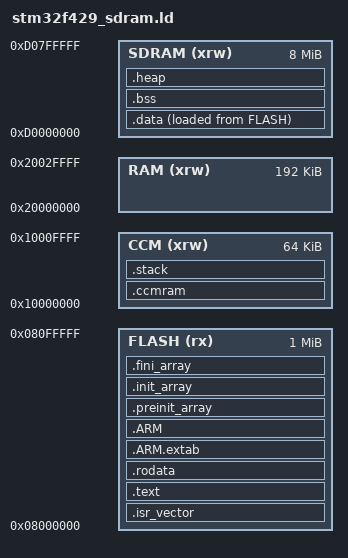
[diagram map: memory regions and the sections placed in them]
/* GNU ARM linker script for fire-f429 applications using onboard SDRAM. */

ENTRY(Reset_Handler)

MEMORY
{
  FLASH  (rx)  : ORIGIN = 0x08000000, LENGTH = 1024K
  RAM    (xrw) : ORIGIN = 0x20000000, LENGTH = 192K
  CCM    (xrw) : ORIGIN = 0x10000000, LENGTH = 64K
  SDRAM  (xrw) : ORIGIN = 0xD0000000, LENGTH = 8M
}

_estack = ORIGIN(CCM) + LENGTH(CCM);
_eram = ORIGIN(SDRAM) + LENGTH(SDRAM);
_Min_Heap_Size = 0x400;
_Min_Stack_Size = 0x1000;

SECTIONS
{
  .isr_vector :
  {
    . = ALIGN(4);
    KEEP(*(.isr_vector))
    . = ALIGN(4);
  } >FLASH

  .text :
  {
    . = ALIGN(4);
    *(.text)
    *(.text*)
    *(.glue_7)
    *(.glue_7t)
    *(.eh_frame)
    KEEP(*(.init))
    KEEP(*(.fini))
    . = ALIGN(4);
    _etext = .;
  } >FLASH

  .rodata :
  {
    . = ALIGN(4);
    *(.rodata)
    *(.rodata*)
    . = ALIGN(4);
  } >FLASH

  .ARM.extab : { *(.ARM.extab* .gnu.linkonce.armextab.*) } >FLASH
  .ARM :
  {
    __exidx_start = .;
    *(.ARM.exidx*)
    __exidx_end = .;
  } >FLASH

  .preinit_array :
  {
    PROVIDE_HIDDEN(__preinit_array_start = .);
    KEEP(*(.preinit_array*))
    PROVIDE_HIDDEN(__preinit_array_end = .);
  } >FLASH

  .init_array :
  {
    PROVIDE_HIDDEN(__init_array_start = .);
    KEEP(*(SORT(.init_array.*)))
    KEEP(*(.init_array*))
    PROVIDE_HIDDEN(__init_array_end = .);
  } >FLASH

  .fini_array :
  {
    PROVIDE_HIDDEN(__fini_array_start = .);
    KEEP(*(SORT(.fini_array.*)))
    PROVIDE_HIDDEN(__fini_array_end = .);
  } >FLASH

  _sidata = LOADADDR(.data);
  .data :
  {
    . = ALIGN(4);
    _sdata = .;
    *(.data)
    *(.data*)
    . = ALIGN(4);
    _edata = .;
  } >SDRAM AT>FLASH

  .bss (NOLOAD) :
  {
    . = ALIGN(4);
    _sbss = .;
    __bss_start__ = _sbss;
    *(.bss)
    *(.bss*)
    *(COMMON)
    . = ALIGN(4);
    _ebss = .;
    __bss_end__ = _ebss;
  } >SDRAM

  . = ALIGN(8);
  _end = .;
  __end__ = .;
  end = .;
  PROVIDE(end = .);

  .heap (NOLOAD) :
  {
    . = ALIGN(8);
    __heap_start__ = .;
    . = . + _Min_Heap_Size;
    __heap_end__ = .;
  } >SDRAM

  .ccmram (NOLOAD) :
  {
    . = ALIGN(8);
    __ccmram_start__ = .;
    *(.ccmram)
    *(.ccmram*)
    . = ALIGN(8);
    __ccmram_end__ = .;
  } >CCM

  .stack (NOLOAD) :
  {
    . = ALIGN(8);
    __stack_start__ = .;
    . = . + _Min_Stack_Size;
    __stack_end__ = .;
  } >CCM

  /DISCARD/ :
  {
    libc.a(*)
    libm.a(*)
    libgcc.a(*)
  }
}
